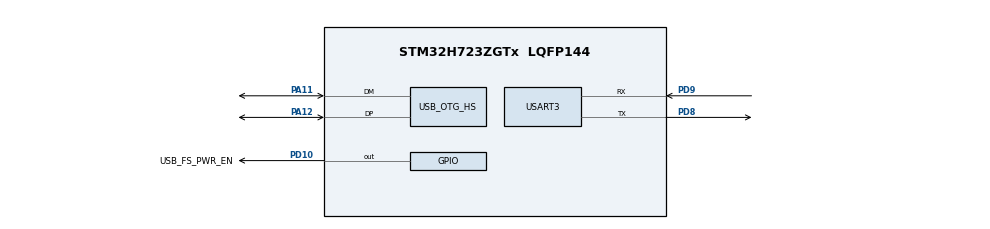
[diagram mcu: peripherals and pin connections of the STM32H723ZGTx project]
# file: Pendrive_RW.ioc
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CORTEX_M7.default_mode_Activation=1
Mcu.Family=STM32H7
Mcu.Name=STM32H723ZGTx
Mcu.Package=LQFP144
NVIC.OTG_HS_IRQn=true\:0\:0\:false\:false\:true\:false\:true\:true\:true
NVIC.PriorityGroup=NVIC_PRIORITYGROUP_4
NVIC.TIM6_DAC_IRQn=true\:15\:0\:false\:false\:true\:false\:false\:true\:true
NVIC.TimeBase=TIM6_DAC_IRQn
NVIC.TimeBaseIP=TIM6
PA11.Mode=Host_FS
PA11.Signal=USB_OTG_HS_DM
PA12.Mode=Host_FS
PA12.Signal=USB_OTG_HS_DP
PD10.GPIO_Label=USB_FS_PWR_EN
PD10.Signal=GPIO_Output
PD8.Mode=Asynchronous
PD8.Signal=USART3_TX
PD9.Mode=Asynchronous
PD9.Signal=USART3_RX
PH0-OSC_IN.Mode=HSE-External-Clock-Source
PH0-OSC_IN.Signal=RCC_OSC_IN
ProjectManager.HeapSize=0x200
ProjectManager.StackSize=0x400
ProjectManager.TargetToolchain=STM32CubeIDE
RCC.ADCFreq_Value=80000000
RCC.APB1Freq_Value=130000000
RCC.APB2Freq_Value=130000000
RCC.APB3Freq_Value=130000000
RCC.APB4Freq_Value=130000000
RCC.CortexFreq_Value=260000000
RCC.D1PPRE=RCC_APB3_DIV2
RCC.D2PPRE1=RCC_APB1_DIV2
RCC.D2PPRE2=RCC_APB2_DIV2
RCC.D3PPRE=RCC_APB4_DIV2
RCC.DIVM1=1
RCC.DIVM2=8
RCC.DIVM3=2
RCC.DIVN1=32
RCC.DIVN2=160
RCC.DIVN3=48
RCC.DIVP1=1
RCC.DIVQ1=3
RCC.DIVQ2=4
RCC.DIVQ3=4
RCC.HCLKFreq_Value=260000000
RCC.HSE_VALUE=8000000
RCC.PLL2FRACN=0
RCC.PLL3FRACN=0
RCC.PLLFRACN=4096
RCC.SYSCLKFreq_VALUE=260000000
RCC.SYSCLKSource=RCC_SYSCLKSOURCE_PLLCLK
RCC.USART234578CLockSelection=RCC_USART234578CLKSOURCE_PLL2
RCC.USBCLockSelection=RCC_USBCLKSOURCE_PLL3
RCC.USBFreq_Value=48000000
STMicroelectronics.X-CUBE-AZRTOS-H7.3.3.0.FX_APP_MEM_POOL_SIZE=2*1024
STMicroelectronics.X-CUBE-AZRTOS-H7.3.3.0.FileXCcFileOoSystemJjFileXJjCore=true
STMicroelectronics.X-CUBE-AZRTOS-H7.3.3.0.GENERATE_FILEX_INIT_CODE=false
STMicroelectronics.X-CUBE-AZRTOS-H7.3.3.0.REG_UX_HOST_CORE=true
STMicroelectronics.X-CUBE-AZRTOS-H7.3.3.0.TX_APP_GENERATE_INIT_CODE=false
STMicroelectronics.X-CUBE-AZRTOS-H7.3.3.0.ThreadXCcRTOSJjThreadXJjCore=true
STMicroelectronics.X-CUBE-AZRTOS-H7.3.3.0.USBXCcUSBJjUSBXJjCoreSystem=true
STMicroelectronics.X-CUBE-AZRTOS-H7.3.3.0.USBXCcUSBJjUSBXJjUXOoHostOoClassOoSTORAGE=true
STMicroelectronics.X-CUBE-AZRTOS-H7.3.3.0.USBXCcUSBJjUSBXJjUXOoHostOoControllers=true
STMicroelectronics.X-CUBE-AZRTOS-H7.3.3.0.USBXCcUSBJjUSBXJjUXOoHostOoCoreStack=true
STMicroelectronics.X-CUBE-AZRTOS-H7.3.3.0.USBX_HOST_SYS_SIZE=22*1024
STMicroelectronics.X-CUBE-AZRTOS-H7.3.3.0.UX_HOST_APP_MEM_POOL_SIZE=30*1024
STMicroelectronics.X-CUBE-AZRTOS-H7.3.3.0.UX_HOST_APP_MEM_POOL_SIZE_STANDALONE=30*1024
STMicroelectronics.X-CUBE-AZRTOS-H7.3.3.0_IsAnAzureRtosMw=true
USART3.VirtualMode-Asynchronous=VM_ASYNC
USB_OTG_HS.VirtualMode-Host_FS=Host_FS
VP_MEMORYMAP_VS_MEMORYMAP.Mode=CurAppReg
VP_STMicroelectronics.X-CUBE-AZRTOS-H7_VS_FileOoSystemJjFileX_6.4.0_3.3.0.Mode=FileOoSystemJjFileX
VP_STMicroelectronics.X-CUBE-AZRTOS-H7_VS_RTOSJjThreadX_6.4.0_3.3.0.Mode=RTOSJjThreadX
VP_STMicroelectronics.X-CUBE-AZRTOS-H7_VS_USBJjUSBX_6.4.0_3.3.0.Mode=USBJjUSBX
VP_SYS_VS_tim6.Mode=TIM6
board=custom

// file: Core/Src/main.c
/* USER CODE BEGIN Header */
/**
  ******************************************************************************
  * @file           : main.c
  * @brief          : Main program body
  ******************************************************************************
  * @attention
  *
  * Copyright (c) 2025 STMicroelectronics.
  * All rights reserved.
  *
  * This software is licensed under terms that can be found in the LICENSE file
  * in the root directory of this software component.
  * If no LICENSE file comes with this software, it is provided AS-IS.
  *
  ******************************************************************************
  */
/* USER CODE END Header */
#include "app_threadx.h"
#include "main.h"
#include "memorymap.h"
#include "usart.h"
#include "gpio.h"

/* USER CODE BEGIN Includes */
#include <stdio.h>
/* USER CODE END Includes */

void SystemClock_Config(void);
static void MPU_Config(void);

/* USER CODE BEGIN 0 */
int __io_putchar(int ch)
{
          HAL_UART_Transmit(&huart3, (uint8_t*)&ch, 1, 0xFF);
          return ch;
}
/* USER CODE END 0 */

int main(void)
{

  /* MPU Configuration--------------------------------------------------------*/
  MPU_Config();

  /* MCU Configuration--------------------------------------------------------*/

  /* Reset of all peripherals, Initializes the Flash interface and the Systick. */
  HAL_Init();

  /* Configure the system clock */
  SystemClock_Config();

  /* Initialize all configured peripherals */
  MX_GPIO_Init();
  MX_USART3_UART_Init();

  MX_ThreadX_Init();

  /* We should never get here as control is now taken by the scheduler */

  /* Infinite loop */
  while (1)
  {

  }
}

void SystemClock_Config(void)
{
  RCC_OscInitTypeDef RCC_OscInitStruct = {0};
  RCC_ClkInitTypeDef RCC_ClkInitStruct = {0};

  /** Supply configuration update enable
  */
  HAL_PWREx_ConfigSupply(PWR_LDO_SUPPLY);

  /** Configure the main internal regulator output voltage
  */
  __HAL_PWR_VOLTAGESCALING_CONFIG(PWR_REGULATOR_VOLTAGE_SCALE0);

  while(!__HAL_PWR_GET_FLAG(PWR_FLAG_VOSRDY)) {}

  /** Initializes the RCC Oscillators according to the specified parameters
  * in the RCC_OscInitTypeDef structure.
  */
  RCC_OscInitStruct.OscillatorType = RCC_OSCILLATORTYPE_HSE;
  RCC_OscInitStruct.HSEState = RCC_HSE_BYPASS;
  RCC_OscInitStruct.PLL.PLLState = RCC_PLL_ON;
  RCC_OscInitStruct.PLL.PLLSource = RCC_PLLSOURCE_HSE;
  RCC_OscInitStruct.PLL.PLLM = 1;
  RCC_OscInitStruct.PLL.PLLN = 32;
  RCC_OscInitStruct.PLL.PLLP = 1;
  RCC_OscInitStruct.PLL.PLLQ = 3;
  RCC_OscInitStruct.PLL.PLLR = 2;
  RCC_OscInitStruct.PLL.PLLRGE = RCC_PLL1VCIRANGE_3;
  RCC_OscInitStruct.PLL.PLLVCOSEL = RCC_PLL1VCOWIDE;
  RCC_OscInitStruct.PLL.PLLFRACN = 4096;
  if (HAL_RCC_OscConfig(&RCC_OscInitStruct) != HAL_OK)
  {
    Error_Handler();
  }

  /** Initializes the CPU, AHB and APB buses clocks
  */
  RCC_ClkInitStruct.ClockType = RCC_CLOCKTYPE_HCLK|RCC_CLOCKTYPE_SYSCLK
                              |RCC_CLOCKTYPE_PCLK1|RCC_CLOCKTYPE_PCLK2
                              |RCC_CLOCKTYPE_D3PCLK1|RCC_CLOCKTYPE_D1PCLK1;
  RCC_ClkInitStruct.SYSCLKSource = RCC_SYSCLKSOURCE_PLLCLK;
  RCC_ClkInitStruct.SYSCLKDivider = RCC_SYSCLK_DIV1;
  RCC_ClkInitStruct.AHBCLKDivider = RCC_HCLK_DIV1;
  RCC_ClkInitStruct.APB3CLKDivider = RCC_APB3_DIV2;
  RCC_ClkInitStruct.APB1CLKDivider = RCC_APB1_DIV2;
  RCC_ClkInitStruct.APB2CLKDivider = RCC_APB2_DIV2;
  RCC_ClkInitStruct.APB4CLKDivider = RCC_APB4_DIV2;

  if (HAL_RCC_ClockConfig(&RCC_ClkInitStruct, FLASH_LATENCY_3) != HAL_OK)
  {
    Error_Handler();
  }
}

 /* MPU Configuration */

void MPU_Config(void)
{
  MPU_Region_InitTypeDef MPU_InitStruct = {0};

  /* Disables the MPU */
  HAL_MPU_Disable();

  /** Initializes and configures the Region and the memory to be protected
  */
  MPU_InitStruct.Enable = MPU_REGION_ENABLE;
  MPU_InitStruct.Number = MPU_REGION_NUMBER0;
  MPU_InitStruct.BaseAddress = 0x0;
  MPU_InitStruct.Size = MPU_REGION_SIZE_4GB;
  MPU_InitStruct.SubRegionDisable = 0x87;
  MPU_InitStruct.TypeExtField = MPU_TEX_LEVEL0;
  MPU_InitStruct.AccessPermission = MPU_REGION_NO_ACCESS;
  MPU_InitStruct.DisableExec = MPU_INSTRUCTION_ACCESS_DISABLE;
  MPU_InitStruct.IsShareable = MPU_ACCESS_SHAREABLE;
  MPU_InitStruct.IsCacheable = MPU_ACCESS_NOT_CACHEABLE;
  MPU_InitStruct.IsBufferable = MPU_ACCESS_NOT_BUFFERABLE;

  HAL_MPU_ConfigRegion(&MPU_InitStruct);
  /* Enables the MPU */
  HAL_MPU_Enable(MPU_PRIVILEGED_DEFAULT);

}

void HAL_TIM_PeriodElapsedCallback(TIM_HandleTypeDef *htim)
{
  if (htim->Instance == TIM6) {
    HAL_IncTick();
  }
}

void Error_Handler(void)
{
  __disable_irq();
  while (1)
  {
  }
}
